# STM32H573 register map
File version: 1.7
CPU: CM33 r0p0, little endian, MPU, FPU, 4 interrupt priority bits
Registers are 32-bit, read-write, reset 0x0 unless marked. A register's access mark holds for its fields unless they carry their own. Offsets are from the block's base; [hi:lo] are bit positions; {n}, {i} and the like mark numbered series; 'fields as' and 'values as' point back to an identical list.

## RCC (part 3 of 3) — Reset and clock controller
Base 0x44020C00
Same registers: SEC_RCC 0x54020C00
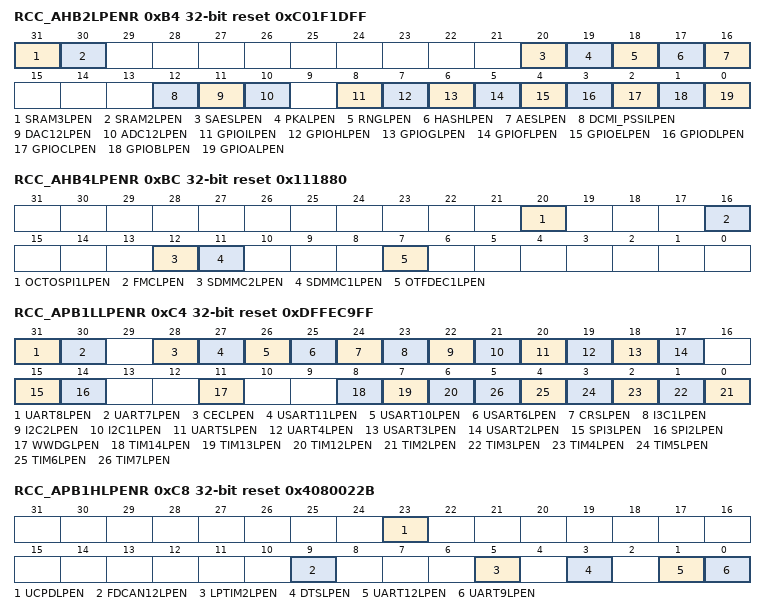
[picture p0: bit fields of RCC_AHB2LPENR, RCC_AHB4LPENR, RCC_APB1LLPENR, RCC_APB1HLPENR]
0xB4 RCC_AHB2LPENR reset 0xC01F1DFF — RCC AHB2 sleep clock register
  [31] SRAM3LPEN — SRAM3 clock enable during sleep mode Set and reset by software.
    0=SRAM3 peripheral clock disabled during sleep mode; 1=SRAM3 peripheral clock enabled during sleep mode (default after reset)
  [30] SRAM2LPEN — SRAM2 clock enable during sleep mode Set and reset by software.
    0=SRAM2 peripheral clock disabled during sleep mode; 1=SRAM2 peripheral clock enabled during sleep mode (default after reset)
  [20] SAESLPEN — SAES clock enable during sleep mode Set and reset by software.
    0=SAES peripheral clock disabled during sleep mode; 1=SAES peripheral clock enabled during sleep mode (default after reset)
  [19] PKALPEN — PKA clock enable during sleep mode Set and reset by software.
    0=PKA peripheral clock disabled during sleep mode; 1=PKA peripheral clock enabled during sleep mode (default after reset)
  [18] RNGLPEN — RNG clock enable during sleep mode Set and reset by software.
    0=RNG peripheral clock disabled during sleep mode; 1=RNG peripheral clock enabled during sleep mode (default after reset)
  [17] HASHLPEN — HASH clock enable during sleep mode Set and reset by software.
    0=HASH peripheral clock disabled during sleep mode; 1=HASH peripheral clock enabled during sleep mode (default after reset)
  [16] AESLPEN — AES clock enable during sleep mode Set and reset by software.
    0=AES peripheral clock disabled during sleep mode; 1=AES peripheral clock enabled during sleep mode (default after reset)
  [12] DCMI_PSSILPEN — digital camera interface clock enable during sleep mode (DCMI or PSSI depending which interface is active) Set and reset by software.
    0=DCMI/PSSI peripheral clock disabled during sleep mode; 1=DCMI/PSSI peripheral clock enabled during sleep mode (default after reset)
  [11] DAC12LPEN — DAC clock enable during sleep mode Set and reset by software.
    0=DAC peripheral clock disabled during sleep mode; 1=DAC peripheral clock enabled during sleep mode (default after reset)
  [10] ADC12LPEN — ADC1 and 2 peripherals clock enable during sleep mode Set and reset by software.
    0=ADC1 and 2 peripherals clock disabled during sleep mode; 1=ADC1 and 2 peripherals clock enabled during sleep mode (default after reset)
  [8] GPIOILPEN — GPIOI clock enable during sleep mode Set and reset by software.
    0=GPIOI peripheral clock disabled during sleep mode; 1=GPIOI peripheral clock enabled during sleep mode (default after reset)
  [7] GPIOHLPEN — GPIOH clock enable during sleep mode Set and reset by software.
    0=GPIOH peripheral clock disabled during sleep mode; 1=GPIOH peripheral clock enabled during sleep mode (default after reset)
  [6] GPIOGLPEN — GPIOG clock enable during sleep mode Set and reset by software.
    0=GPIOG peripheral clock disabled during sleep mode; 1=GPIOG peripheral clock enabled during sleep mode (default after reset)
  [5] GPIOFLPEN — GPIOF clock enable during sleep mode Set and reset by software.
    0=GPIOF peripheral clock disabled during sleep mode; 1=GPIOF peripheral clock enabled during sleep mode (default after reset)
  [4] GPIOELPEN — GPIOE clock enable during sleep mode Set and reset by software.
    0=GPIOE peripheral clock disabled during sleep mode; 1=GPIOE peripheral clock enabled during sleep mode (default after reset)
  [3] GPIODLPEN — GPIOD clock enable during sleep mode Set and reset by software.
    0=GPIOD peripheral clock disabled during sleep mode; 1=GPIOD peripheral clock enabled during sleep mode (default after reset)
  [2] GPIOCLPEN — GPIOC clock enable during sleep mode Set and reset by software.
    0=GPIOC peripheral clock disabled during sleep mode; 1=GPIOC peripheral clock enabled during sleep mode (default after reset)
  [1] GPIOBLPEN — GPIOB clock enable during sleep mode Set and reset by software.
    0=GPIOB peripheral clock disabled during sleep mode; 1=GPIOB peripheral clock enabled during sleep mode (default after reset)
  [0] GPIOALPEN — GPIOA clock enable during sleep mode Set and reset by software.
    0=GPIOA peripheral clock disabled during sleep mode; 1=GPIOA peripheral clock enabled during sleep mode (default after reset)
0xBC RCC_AHB4LPENR reset 0x111880 — RCC AHB4 sleep clock register
  [20] OCTOSPI1LPEN — OCTOSPI1 clock enable during sleep mode Set and reset by software.
    0=OCTOSPI1 peripheral clock disabled during sleep mode; 1=OCTOSPI1 peripheral clock enabled during sleep mode (default after reset)
  [16] FMCLPEN — FMC clock enable during sleep mode Set and reset by software.
    0=FMC peripheral clock disabled during sleep mode; 1=FMC peripheral clock enabled during sleep mode (default after reset)
  [12] SDMMC2LPEN — SDMMC2 and SDMMC2 delay peripheral clock enable during sleep mode Set and reset by software.
    0=SDMMC2 and SDMMC2 delay peripherals clock disabled during sleep mode; 1=SDMMC2 and SDMMC2 delay peripherals clock enabled during sleep mode (default after reset)
  [11] SDMMC1LPEN — SDMMC1 and SDMMC1 delay peripheral clock enable during sleep mode Set and reset by software
    0=SDMMC1 and SDMMC1 delay peripherals clock disabled during sleep mode; 1=SDMMC1 and SDMMC1 delay peripherals clock enabled during sleep mode (default after reset)
  [7] OTFDEC1LPEN — OTFDEC1 clock enable during sleep mode Set and reset by software.
    0=OTFDEC1 peripheral clock disabled during sleep mode; 1=OTFDEC1 peripheral clock enabled during sleep mode (default after reset)
0xC4 RCC_APB1LLPENR reset 0xDFFEC9FF — RCC APB1 sleep clock register
  [31] UART8LPEN — UART8 clock enable during sleep mode Set and reset by software.
    0=UART8 peripheral clock disabled during sleep mode; 1=UART8 peripheral clock enabled during sleep mode (default after reset)
  [30] UART7LPEN — UART7 clock enable during sleep mode Set and reset by software.
    0=UART7 peripheral clock disabled during sleep mode; 1=UART7 peripheral clock enabled during sleep mode (default after reset)
  [28] CECLPEN — HDMI-CEC clock enable during sleep mode Set and reset by software.
    0=HDMI-CEC peripheral clock disabled during sleep mode; 1=HDMI-CEC peripheral clock enabled during sleep mode (default after reset)
  [27] USART11LPEN — USART11 clock enable during sleep mode Set and reset by software.
    0=USART11 peripheral clock disabled during sleep mode; 1=USART11 peripheral clock enabled during sleep mode (default after reset)
  [26] USART10LPEN — USART10 clock enable during sleep mode Set and reset by software.
    0=USART10 peripheral clock disabled during sleep mode; 1=USART10 peripheral clock enabled during sleep mode (default after reset)
  [25] USART6LPEN — USART6 clock enable during sleep mode Set and reset by software.
    0=USART6 peripheral clock disabled during sleep mode; 1=USART6 peripheral clock enabled during sleep mode (default after reset)
  [24] CRSLPEN — CRS clock enable during sleep mode Set and reset by software.
    0=CRS peripheral clock disabled during sleep mode; 1=CRS peripheral clock enabled during sleep mode (default after reset)
  [23] I3C1LPEN — I3C1 clock enable during sleep mode Set and reset by software.
    0=I3C1 peripheral clock disabled during sleep mode; 1=I3C1 peripheral clock enabled during sleep mode (default after reset)
  [22] I2C2LPEN — I2C2 clock enable during sleep mode Set and reset by software.
    0=I2C2 peripheral clock disabled during sleep mode; 1=I2C2 peripheral clock enabled during sleep mode (default after reset)
  [21] I2C1LPEN — I2C1 clock enable during sleep mode Set and reset by software.
    0=I2C1 peripheral clock disabled during sleep mode; 1=I2C1 peripheral clock enabled during sleep mode (default after reset)
  [20] UART5LPEN — UART5 clock enable during sleep mode Set and reset by software.
    0=UART5 peripheral clock disabled during sleep mode; 1=UART5 peripheral clock enabled during sleep mode (default after reset)
  [19] UART4LPEN — UART4 clock enable during sleep mode Set and reset by software.
    0=UART4 peripheral clock disabled during sleep mode; 1=UART4 peripheral clock enabled during sleep mode (default after reset)
  [18] USART3LPEN — USART3 clock enable during sleep mode Set and reset by software.
    0=USART3 peripheral clock disabled during sleep mode; 1=USART3 peripheral clock enabled during sleep mode (default after reset)
  [17] USART2LPEN — USART2 clock enable during sleep mode Set and reset by software.
    0=USART2 peripheral clock disabled during sleep mode; 1=USART2 peripheral clock enabled during sleep mode (default after reset)
  [15] SPI3LPEN — SPI3 clock enable during sleep mode Set and reset by software.
    0=SPI3 peripheral clock disabled during sleep mode; 1=SPI3 peripheral clock enabled during sleep mode (default after reset)
  [14] SPI2LPEN — SPI2 clock enable during sleep mode Set and reset by software.
    0=SPI2 peripheral clock disabled during sleep mode; 1=SPI2 peripheral clock enabled during sleep mode (default after reset)
  [11] WWDGLPEN — WWDG clock enable during sleep mode Set and reset by software.
    0=WWDG peripheral clock disabled during sleep mode; 1=WWDG peripheral clock enabled during sleep mode (default after reset)
  [8] TIM14LPEN — TIM14 clock enable during sleep mode Set and reset by software.
    0=TIM14 peripheral clock disabled during sleep mode; 1=TIM14 peripheral clock enabled during sleep mode (default after reset)
  [7] TIM13LPEN — TIM13 clock enable during sleep mode Set and reset by software.
    0=TIM13 peripheral clock disabled during sleep mode; 1=TIM13 peripheral clock enabled during sleep mode (default after reset)
  [6] TIM12LPEN — TIM12 clock enable during sleep mode Set and reset by software.
    0=TIM12 peripheral clock disabled during sleep mode; 1=TIM12 peripheral clock enabled during sleep mode (default after reset)
  [n-2] TIM{n}LPEN (n=2..7) — TIM{n} clock enable during sleep mode Set and reset by software.
    0=TIM{n} peripheral clock disabled during sleep mode; 1=TIM{n} peripheral clock enabled during sleep mode (default after reset)
0xC8 RCC_APB1HLPENR reset 0x4080022B — RCC APB1 sleep clock register
  [23] UCPDLPEN — UCPD clock enable during sleep mode Set and reset by software.
    0=UCPD peripheral clock disabled during sleep mode; 1=UCPD peripheral clock enabled during sleep mode (default after reset)
  [9] FDCAN12LPEN — FDCAN1 and FDCAN2 peripheral clock enable during sleep mode Set and reset by software.
    0=FDCAN1 and FDCAN2 peripheral clock disabled during sleep mode; 1=FDCAN1 and FDCAN2 peripheral clock enabled during sleep mode (default after reset)
  [5] LPTIM2LPEN — LPTIM2 clock enable during sleep mode Set and reset by software.
    0=LPTIM2 peripheral clock disabled during sleep mode; 1=LPTIM2 peripheral clock enabled during sleep mode (default after reset)
  [3] DTSLPEN — DTS clock enable during sleep mode Set and reset by software.
    0=DTS peripheral clock disabled during sleep mode; 1=DTS peripheral clock enabled during sleep mode (default after reset)
  [1] UART12LPEN — UART12 clock enable during sleep mode Set and reset by software.
    0=UART12 peripheral clock disabled during sleep mode; 1=UART12 peripheral clock enabled during sleep mode (default after reset)
  [0] UART9LPEN — UART9 clock enable during sleep mode Set and reset by software.
    0=UART9 peripheral clock disabled during sleep mode; 1=resets UART9 peripheral clock enabled during sleep mode (default after reset)
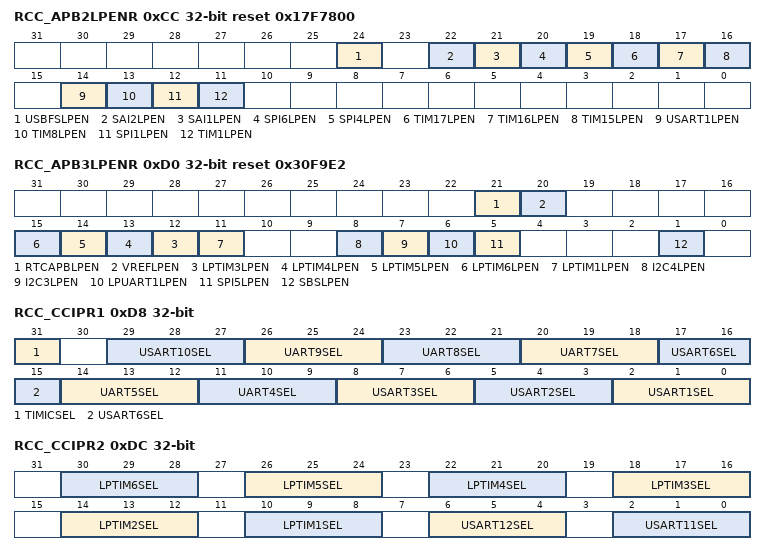
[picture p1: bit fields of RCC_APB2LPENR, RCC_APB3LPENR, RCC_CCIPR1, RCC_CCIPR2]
0xCC RCC_APB2LPENR reset 0x17F7800 — RCC APB2 sleep clock register
  [24] USBFSLPEN — USBFS clock enable during sleep mode Set and reset by software.
    0=USBFS peripheral clock disabled during sleep mode; 1=USBFS peripheral clock enabled during sleep mode (default after reset)
  [22] SAI2LPEN — SAI2 clock enable during sleep mode Set and reset by software.
    0=SAI2 peripheral clock disabled during sleep mode; 1=SAI2 peripheral clock enabled during sleep mode (default after reset)
  [21] SAI1LPEN — SAI1 clock enable during sleep mode Set and reset by software.
    0=SAI1 peripheral clock disabled during sleep mode; 1=SAI1 peripheral clock enabled during sleep mode (default after reset)
  [20] SPI6LPEN — SPI6 clock enable during sleep mode Set and reset by software.
    0=SPI6 peripheral clock disabled during sleep mode; 1=SPI6 peripheral clock enabled during sleep mode (default after reset)
  [19] SPI4LPEN — SPI4 clock enable during sleep mode Set and reset by software.
    0=SPI4 peripheral clock disabled during sleep mode; 1=SPI4 peripheral clock enabled during sleep mode (default after reset)
  [18] TIM17LPEN — TIM17 clock enable during sleep mode Set and reset by software.
    0=TIM17 peripheral clock disabled during sleep mode; 1=TIM17 peripheral clock enabled during sleep mode (default after reset)
  [17] TIM16LPEN — TIM16 clock enable during sleep mode Set and reset by software.
    0=TIM16 peripheral clock disabled during sleep mode; 1=TIM16 peripheral clock enabled during sleep mode (default after reset)
  [16] TIM15LPEN — TIM15 clock enable during sleep mode Set and reset by software.
    0=TIM15 peripheral clock disabled during sleep mode; 1=TIM15 peripheral clock enabled during sleep mode (default after reset)
  [14] USART1LPEN — USART1 clock enable during sleep mode Set and reset by software.
    0=USART1 peripheral clock disabled during sleep mode; 1=USART1 peripheral clock enabled during sleep mode (default after reset)
  [13] TIM8LPEN — TIM8 clock enable during sleep mode Set and reset by software.
    0=TIM8 peripheral clock disabled during sleep mode; 1=TIM8 peripheral clock enabled during sleep mode (default after reset)
  [12] SPI1LPEN — SPI1 clock enable during sleep mode Set and reset by software.
    0=SPI1 peripheral clock disabled during sleep mode; 1=SPI1 peripheral clock enabled during sleep mode (default after reset)
  [11] TIM1LPEN — TIM1 clock enable during sleep mode Set and reset by software.
    0=TIM1 peripheral clock disabled during sleep mode; 1=TIM1 peripheral clock enabled during sleep mode (default after reset)
0xD0 RCC_APB3LPENR reset 0x30F9E2 — RCC APB4 sleep clock register
  [21] RTCAPBLPEN — RTC APB interface clock enable during sleep mode Set and reset by software.
    0=RTC APB interface clock disabled during sleep mode; 1=RTC APB interface clock enabled during sleep mode (default after reset)
  [20] VREFLPEN — VREF clock enable during sleep mode Set and reset by software.
    0=VREF peripheral clock disabled during sleep mode; 1=VREF peripheral clock enabled during sleep mode (default after reset)
  [n+9] LPTIM{n}LPEN (n=3..6) — LPTIM{n} clock enable during sleep mode Set and reset by software.
    0=LPTIM{n} peripheral clock disabled during sleep mode; 1=LPTIM{n} peripheral clock enabled during sleep mode (default after reset)
  [11] LPTIM1LPEN — LPTIM1 clock enable during sleep mode Set and reset by software.
    0=LPTIM1 peripheral clock disabled during sleep mode; 1=LPTIM1 peripheral clock enabled during sleep mode (default after reset)
  [8] I2C4LPEN — I2C4 clock enable during sleep mode Set and reset by software.
    0=I2C4 peripheral clock disabled during sleep mode; 1=I2C4 peripheral clock enabled during sleep mode (default after reset)
  [7] I2C3LPEN — I2C3 clock enable during sleep mode Set and reset by software.
    0=I2C3 peripheral clock disabled during sleep mode; 1=I2C3 peripheral clock enabled during sleep mode (default after reset)
  [6] LPUART1LPEN — LPUART1 clock enable during sleep mode Set and reset by software.
    0=LPUART1 peripheral clock disabled during sleep mode; 1=LPUART1 peripheral clock enabled during sleep mode (default after reset)
  [5] SPI5LPEN — SPI5 clock enable during Slsleepeep mode Set and reset by software.
    0=SPI5 peripheral clock disabled during sleep mode; 1=SPI5 peripheral clock enabled during Slesleepep mode (default after reset)
  [1] SBSLPEN — SBS clock enable during sleep mode Set and reset by software.
    0=SBS peripheral clock disabled during sleep mode; 1=SBS peripheral clock enabled during sleep mode (default after reset)
0xD8 RCC_CCIPR1 — RCC kernel clock configuration register
  [31] TIMICSEL — TIM12, TIM15 and LPTIM2 input capture source selection Set and reset by software.
    0=No internal clock available for timers input capture (default after reset); 1=hsi_ker_ck/1024, hsi_ker_ck/8 and csi_ker_ck/128 selected for timers input capture
  [29:27] USART10SEL — USART10 kernel clock source selection others: reserved, the kernel clock is disabled
    0=rcc_pclk1 selected as kernel clock (default after reset); 1=pll2_q_ck selected as kernel clock; 2=pll3_q_ck selected as kernel clock; 3=hsi_ker_ck selected as kernel clock; 4=csi_ker_ck selected as kernel clock; 5=lse_ck selected as kernel clock
  [26:24] UART9SEL — UART9 kernel clock source selection others: reserved, the kernel clock is disabled
    values as USART10SEL
  [23:21] UART8SEL — UART8 kernel clock source selection others: reserved, the kernel clock is disabled
    values as USART10SEL
  [20:18] UART7SEL — UART7 kernel clock source selection others: reserved, the kernel clock is disabled
    values as USART10SEL
  [17:15] USART6SEL — USART6 kernel clock source selection others: reserved, the kernel clock is disabled
    values as USART10SEL
  [14:12] UART5SEL — UART5 kernel clock source selection others: reserved, the kernel clock is disabled
    values as USART10SEL
  [11:9] UART4SEL — UART4 kernel clock source selection others: reserved, the kernel clock is disabled
    values as USART10SEL
  [8:6] USART3SEL — USART3 kernel clock source selection Set and reset by software. others: reserved, the kernel clock is disabled
    values as USART10SEL
  [5:3] USART2SEL — USART2 kernel clock source selection Set and reset by software. others: reserved, the kernel clock is disabled
    values as USART10SEL
  [2:0] USART1SEL — USART1 kernel clock source selection Set and reset by software. others: reserved, the kernel clock is disabled
    0=rcc_pclk2 selected as kernel clock (default after reset); 1=pll2_q_ck selected as kernel clock; 2=pll3_q_ck selected as kernel clock; 3=hsi_ker_ck selected as kernel clock; 4=csi_ker_ck selected as kernel clock; 5=lse_ck selected as kernel clock
0xDC RCC_CCIPR2 — RCC kernel clock configuration register
  [4n+6:4n+4] LPTIM{n}SEL (n=3..6) — LPTIM{n} kernel clock source selection others: reserved, the kernel clock is disabled
    0=rcc_pclk3 selected as kernel clock (default after reset); 1=pll2_p_ck selected as kernel clock; 2=pll3_r_ck selected as kernel clock; 3=lse_ker_ck selected as kernel clock; 4=lsi_ker_ck selected as kernel clock; 5=per_ck selected as kernel clock
  [14:12] LPTIM2SEL — LPTIM2 kernel clock source selection others: reserved, the kernel clock is disabled
    0=rcc_pclk1 selected as kernel clock (default after reset); 1=pll2_p_ck selected as kernel clock; 2=pll3_r_ck selected as kernel clock; 3=lse_ker_ck selected as kernel clock; 4=lsi_ker_ck selected as kernel clock; 5=per_ck selected as kernel clock
  [10:8] LPTIM1SEL — LPTIM1 kernel clock source selection others: reserved, the kernel clock is disabled
    values as LPTIM3SEL
  [6:4] USART12SEL — USART12 kernel clock source selection Set and reset by software. others: reserved, the kernel clock is disabled
    values as RCC_CCIPR1.USART10SEL
  [2:0] USART11SEL — USART11 kernel clock source selection Set and reset by software. others: reserved, the kernel clock is disabled
    values as RCC_CCIPR1.USART10SEL
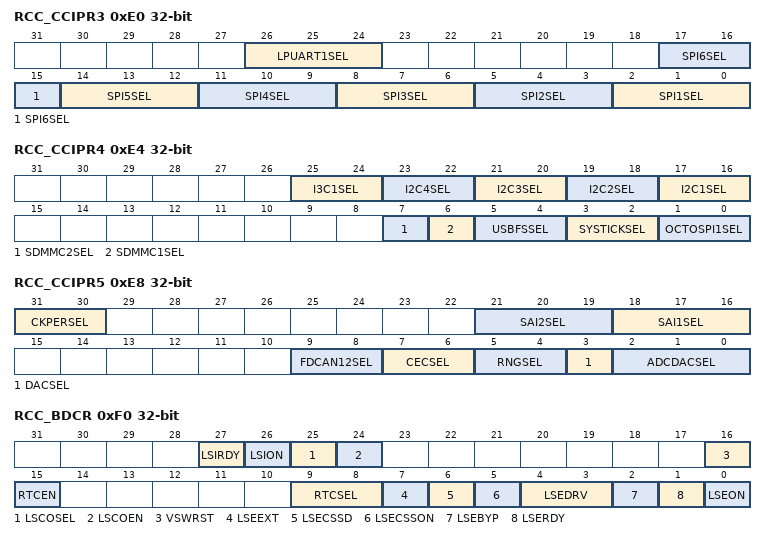
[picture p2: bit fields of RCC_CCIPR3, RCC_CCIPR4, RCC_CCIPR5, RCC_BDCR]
0xE0 RCC_CCIPR3 — RCC kernel clock configuration register
  [26:24] LPUART1SEL — LPUART1 kernel clock source selection others: reserved, the kernel clock is disabled
    0=rcc_pclk3 s elected as kernel clock (default after reset); 1=pll2_q_ck selected as kernel clock; 2=pll3_q_ck selected as kernel clock; 3=hsi_ker_ck selected as kernel clock; 4=csi_ker_ck selected as kernel clock; 5=lse_ck selected as kernel clock
  [17:15] SPI6SEL — SPI6 kernel clock source selection others: reserved, the kernel clock is disabled
    0=rcc_pclk2 selected as kernel clock (default after reset); 1=pll2_q_ck selected as kernel clock; 2=pll3_q_ck selected as kernel clock; 3=hsi_ker_ck selected as kernel clock; 4=csi_ker_ck selected as kernel clock; 5=hse_ck selected as kernel clock
  [14:12] SPI5SEL — SPI5 kernel clock source selection others: reserved, the kernel clock is disabled
    0=rcc_pclk3 selected as kernel clock (default after reset); 1=pll2_q_ck selected as kernel clock; 2=pll3_q_ck selected as kernel clock; 3=hsi_ker_ck selected as kernel clock; 4=csi_ker_ck selected as kernel clock; 5=hse_ck selected as kernel clock
  [11:9] SPI4SEL — SPI4 kernel clock source selection others: reserved, the kernel clock is disabled
    values as SPI6SEL
  [8:6] SPI3SEL — SPI3 kernel clock source selection Set and reset by software. others: reserved, the kernel clock is disabled
    0=pll1_q_ck selected as kernel clock (default after reset); 1=pll2_p_ck selected as kernel clock; 2=pll3_p_ck selected as kernel clock; 3=AUDIOCLK selected as kernel clock; 4=per_ck selected as kernel clock
  [5:3] SPI2SEL — SPI2 kernel clock source selection Set and reset by software. others: reserved, the kernel clock is disabled
    values as SPI3SEL
  [2:0] SPI1SEL — SPI1 kernel clock source selection Set and reset by software. others: reserved, the kernel clock is disabled
    values as SPI3SEL
0xE4 RCC_CCIPR4 — RCC kernel clock configuration register
  [25:24] I3C1SEL — I3C1 kernel clock source selection
    0=rcc_pclk3 selected as kernel clock (default after reset); 1=pll3_r_ck selected as kernel clock; 2=hsi_ker_ck selected as kernel clock; 3=no clock selected
  [23:22] I2C4SEL — I2C4 kernel clock source selection
    0=rcc_pclk3 selected as kernel clock (default after reset); 1=pll3_r_ck selected as kernel clock; 2=hsi_ker_ck selected as kernel clock; 3=csi_ker_ck selected as kernel clock
  [21:20] I2C3SEL — I2C3 kernel clock source selection
    values as I2C4SEL
  [19:18] I2C2SEL — I2C2 kernel clock source selection
    0=rcc_pclk1 selected as kernel clock (default after reset); 1=pll3_r_ck selected as kernel clock; 2=hsi_ker_ck selected as kernel clock; 3=csi_ker_ck selected as kernel clock
  [17:16] I2C1SEL — I2C1 kernel clock source selection
    values as I2C2SEL
  [7] SDMMC2SEL — SDMMC2 kernel clock source selection
    0=pll1_q_ck selected as kernel clock (default after reset); 1=pll2_r_ck selected as kernel clock
  [6] SDMMC1SEL — SDMMC1 kernel clock source selection
    values as SDMMC2SEL
  [5:4] USBFSSEL — USBFS kernel clock source selection
    0=no clock is selected as kernel clock (default after reset); 1=pll1_q_ck selected as kernel clock; 2=pll3_q_ck selected as kernel clock; 3=hsi48_ker_ck selected as kernel clock
  [3:2] SYSTICKSEL — SYSTICK clock source selection Note: rcc_hclk frequency must be four times higher than lsi_ker_ck/lse_ck (period (LSI/LSE) greater than or equal 4 * period (HCLK).
    0=rcc_hclk/8 selected as clock source (default after reset); 1=lsi_ker_ck[1] selected as clock source; 2=lse_ck[1] selected as clock source; 3=reserved, the kernel clock is disabled
  [1:0] OCTOSPI1SEL — OCTOSPI1 kernel clock source selection Set and reset by software.
    0=rcc_hclk4 selected as kernel clock (default after reset); 1=pll1_q_ck selected as kernel clock; 2=pll2_r_ck selected as kernel clock; 3=per_ck selected as kernel clock
0xE8 RCC_CCIPR5 — RCC kernel clock configuration register
  [31:30] CKPERSEL — per_ck clock source selection
    0=hsi_ker_ck selected as kernel clock (default after reset); 1=csi_ker_ck selected as kernel clock; 2=hse_ck selected as kernel clock; 3=reserved, the per_ck clock is disabled
  [21:19] SAI2SEL — SAI2 kernel clock source selection others: reserved, the kernel clock is disabled
    values as RCC_CCIPR3.SPI3SEL
  [18:16] SAI1SEL — SAI1 kernel clock source selection others: reserved, the kernel clock is disabled
    values as RCC_CCIPR3.SPI3SEL
  [9:8] FDCAN12SEL — FDCAN1 and FDCAN2 kernel clock source selection
    0=hse_ck selected as kernel clock (default after reset); 1=pll1_q_ck selected as kernel clock; 2=pll2_q_ck selected as kernel clock; 3=reserved, the kernel clock is disabled
  [7:6] CECSEL — HSMI-CEC kernel clock source selection
    0=lse_ck selected as kernel clock (default after reset); 1=lsi_ker_ck selected as kernel clock; 2=csi_ker_ck/122 selected as kernel clock; 3=reserved, the kernel clock is disabled
  [5:4] RNGSEL — RNG kernel clock source selection
    0=hsi48_ker_ck selected as kernel clock (default after reset); 1=pll1_q_ck selected as kernel clock; 2=lse_ck selected as kernel clock; 3=lsi_ker_ck selected as kernel clock
  [3] DACSEL — DAC hold clock
    0=dac_hold_ck selected as kernel clock (default after reset); 1=dac_hold_ck selected as kernel clock
  [2:0] ADCDACSEL — ADC and DAC kernel clock source selection others: reserved, the kernel clock is disabled
    0=rcc_hclk selected as kernel clock (default after reset); 1=sys_ck selected as kernel clock; 2=pll2_r_ck selected as kernel clock; 3=hse_ck selected as kernel clock; 4=hsi_ker_ck selected as kernel clock; 5=csi_ker_ck selected as kernel clock
0xF0 RCC_BDCR — RCC Backup domain control register
  [27] LSIRDY — LSI oscillator ready Set and cleared by hardware to indicate when the LSI oscillator is stable. After the LSION bit is cleared, LSIRDY goes low after three internal low-speed oscillator clock cycles. This bit is set when the LSI is used by IWDG or RTC, even if LSION = 0.
    0=LSI oscillator not ready; 1=LSI oscillator ready
  [26] LSION — LSI oscillator enable Set and cleared by software.
    0=LSI oscillator off; 1=LSI oscillator on
  [25] LSCOSEL — Low-speed clock output selection Set and cleared by software.
    0=LSI clock selected; 1=LSE clock selected
  [24] LSCOEN — Low-speed clock output (LSCO) enable Set and cleared by software.
    0=LSCO output disabled; 1=LSCO output enabled
  [16] VSWRST — VSwitch domain software reset Set and reset by software.
    0=reset not activated (default after Backup domain reset); 1=resets the entire VSW domain
  [15] RTCEN — RTC clock enable Set and reset by software.
    0=rtc_ck disabled (default after Backup domain reset); 1=rtc_ck enabled
  [9:8] RTCSEL — RTC clock source selection Set by software to select the clock source for the RTC. These bits can be written only one time (except in case of failure detection on LSE). These bits must be written before LSECSSON is enabled. The VSWRST bit can be used to reset them, then it can be written one time again. If HSE is selected as RTC clock, this clock is lost when the system is in Stop mode or in case of a pin reset (NRST).
    0=no clock (default after Backup domain reset); 1=LSE selected as RTC clock; 2=LSI selected as RTC clock; 3=HSE divided by RTCPRE value selected as RTC clock
  [7] LSEEXT — low-speed external clock type in bypass mode Set and reset by software to select the external clock type (analog or digital). The external clock must be enabled with the LSEON bit, to be used by the device. The LSEEXT bit can be written only if the LSE oscillator is disabled.
    0=LSE in analog mode (default after Backup domain reset); 1=LSE in digital mode (do not use if RTC is active)
  [6] LSECSSD — LSE clock security system failure detection Set by hardware to indicate when a failure has been detected by the clock security system on the external 32 kHz oscillator.
    0=no failure detected on 32 kHz oscillator (default after Backup domain reset); 1=failure detected on 32 kHz oscillator
  [5] LSECSSON — LSE clock security system enable Set by software to enable the clock security system on 32 kHz oscillator. LSECSSON must be enabled after LSE is enabled (LSEON enabled) and ready (LSERDY set by hardware) and after RTCSEL is selected. Once enabled, this bit cannot be disabled, except after a LSE failure detection (LSECSSD = 1). In that case the software must disable LSECSSON.
    0=CSS on 32 kHz oscillator OFF (default after Backup domain reset); 1=CSS on 32 kHz oscillator ON
  [4:3] LSEDRV — LSE oscillator driving capability Set by software to select the driving capability of the LSE oscillator. These bit can be written only if LSE oscillator is disabled (LSEON = 0 and LSERDY = 0).
    0=lowest drive (default after Backup domain reset); 1=medium-low drive; 2=medium-high drive; 3=highest drive
  [2] LSEBYP — LSE oscillator bypass Set and reset by software to bypass oscillator in debug mode. This bit must not be written when the LSE is enabled (by LSEON) or ready (LSERDY = 1)
    0=LSE oscillator not bypassed (default after Backup domain reset); 1=LSE oscillator bypassed
  [1] LSERDY — LSE oscillator ready Set and reset by hardware to indicate when the LSE is stable. This bit needs 6 cycles of lse_ck clock to fall down after LSEON has been set to 0.
    0=LSE oscillator not ready (default after Backup domain reset); 1=LSE oscillator ready
  [0] LSEON — LSE oscillator enabled Set and reset by software.
    0=LSE oscillator OFF (default after Backup domain reset); 1=LSE oscillator ON
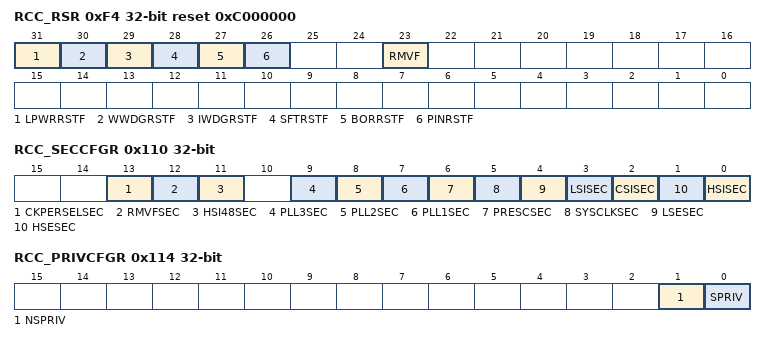
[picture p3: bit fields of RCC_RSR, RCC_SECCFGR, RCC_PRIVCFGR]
0xF4 RCC_RSR reset 0xC000000 — RCC reset status register
  [31] LPWRRSTF — Low-power reset flag Set by hardware when a reset occurs due to Stop or Standby mode entry, whereas the corresponding nRST_STOP, nRST_STBY option bit is cleared. Cleared by writing to the RMVF bit.
    0=No illegal low-power mode reset occurred; 1=Illegal low-power mode reset occurred
  [30] WWDGRSTF — window watchdog reset flag Reset by software by writing the RMVF bit. Set by hardware when a window watchdog reset occurs.
    0=no window watchdog reset occurred from WWDG (default after power-on reset); 1=window watchdog reset occurred from WWDG
  [29] IWDGRSTF — independent watchdog reset flag Reset by software by writing the RMVF bit. Set by hardware when an independent watchdog reset occurs.
    0=no independent watchdog reset occurred (default after power-on reset); 1=independent watchdog reset occurred
  [28] SFTRSTF — system reset from CPU reset flag Reset by software by writing the RMVF bit. Set by hardware when the system reset is due to CPU.The CPU can generate a system reset by writing SYSRESETREQ bit of AIRCR register of the core M33.
    0=no CPU software reset occurred (default after power-on reset); 1=a system reset has been generated by the CPU
  [27] BORRSTF — BOR reset flag Reset by software by writing the RMVF bit. Set by hardware when a BOR reset occurs (pwr_bor_rst).
    0=no BOR reset occurred; 1=BOR reset occurred (default after power-on reset)
  [26] PINRSTF — pin reset flag (NRST) Reset by software by writing the RMVF bit. Set by hardware when a reset from pin occurs.
    0=no reset from pin occurred; 1=reset from pin occurred (default after power-on reset)
  [23] RMVF — remove reset flag Set and reset by software to reset the value of the reset flags.
    0=reset of the reset flags not activated (default after power-on reset); 1=resets the value of the reset flags
0x110 RCC_SECCFGR — RCC secure configuration register
  [all] fields
    0=non secure; 1=secure
  [13] CKPERSELSEC — per_ck selection security Set and reset by software.
  [12] RMVFSEC — Remove reset flag security Set and reset by software.
  [11] HSI48SEC — HSI48 clock configuration and status bits security Set and reset by software.
  [9] PLL3SEC — PLL3 clock configuration and status bits security Set and reset by software.
  [8] PLL2SEC — PLL2 clock configuration and status bits security Set and reset by software.
  [7] PLL1SEC — PLL1 clock configuration and status bits security Set and reset by software.
  [6] PRESCSEC — AHBx/APBx prescaler configuration bits security Set and reset by software.
  [5] SYSCLKSEC — SYSCLK clock selection, STOPWUCK bit, clock output on MCO configuration security Set and reset by software.
  [4] LSESEC — LSE clock configuration and status bits security Set and reset by software.
  [3] LSISEC — LSI clock configuration and status bits security Set and reset by software.
  [2] CSISEC — CSI clock configuration and status bits security Set and reset by software.
  [1] HSESEC — HSE clock configuration bits, status bits and HSE_CSS security Set and reset by software.
  [0] HSISEC — HSI clock configuration and status bits security Set and reset by software.
0x114 RCC_PRIVCFGR — RCC privilege configuration register
  [1] NSPRIV — RCC non-secure functions privilege configuration Set and reset by software. This bit can be written only by privileged access, secure or non-secure.
    0=Read and write to RCC non-secure functions can be done by privileged or unprivileged access; 1=Read and write to RCC non-secure functions can be done by privileged access only
  [0] SPRIV — RCC secure functions privilege configuration Set and reset by software. This bit can be written only by a secure privileged access.
    0=Read and write to RCC secure functions can be done by privileged or unprivileged access; 1=Read and write to RCC secure functions can be done by privileged access only
